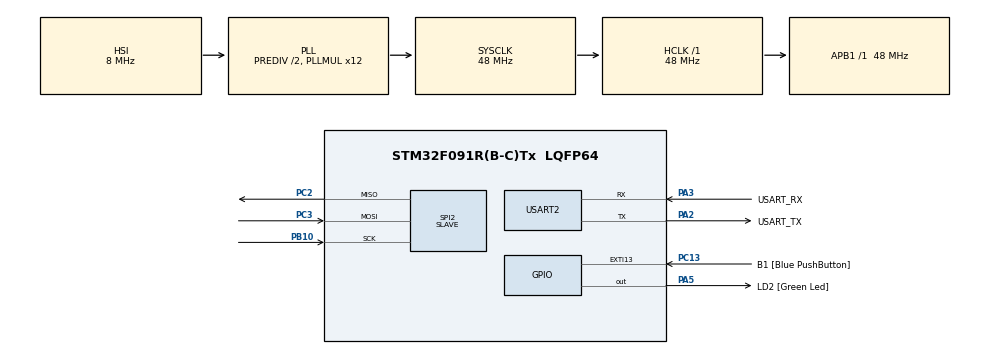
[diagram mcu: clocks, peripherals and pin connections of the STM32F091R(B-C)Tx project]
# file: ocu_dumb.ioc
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Dma.Request0=SPI2_RX
Dma.Request1=SPI2_TX
Dma.SPI2_RX.0.Direction=DMA_PERIPH_TO_MEMORY
Dma.SPI2_RX.0.Instance=DMA1_Channel4
Dma.SPI2_RX.0.MemDataAlignment=DMA_MDATAALIGN_BYTE
Dma.SPI2_RX.0.MemInc=DMA_MINC_ENABLE
Dma.SPI2_RX.0.Mode=DMA_NORMAL
Dma.SPI2_RX.0.PeriphDataAlignment=DMA_PDATAALIGN_BYTE
Dma.SPI2_RX.0.PeriphInc=DMA_PINC_DISABLE
Dma.SPI2_RX.0.Priority=DMA_PRIORITY_LOW
Dma.SPI2_TX.1.Direction=DMA_MEMORY_TO_PERIPH
Dma.SPI2_TX.1.Instance=DMA1_Channel5
Dma.SPI2_TX.1.MemDataAlignment=DMA_MDATAALIGN_BYTE
Dma.SPI2_TX.1.MemInc=DMA_MINC_ENABLE
Dma.SPI2_TX.1.Mode=DMA_NORMAL
Dma.SPI2_TX.1.PeriphDataAlignment=DMA_PDATAALIGN_BYTE
Dma.SPI2_TX.1.PeriphInc=DMA_PINC_DISABLE
Dma.SPI2_TX.1.Priority=DMA_PRIORITY_LOW
Mcu.Family=STM32F0
Mcu.Name=STM32F091R(B-C)Tx
Mcu.Package=LQFP64
NVIC.DMA1_Ch4_7_DMA2_Ch3_5_IRQn=true\:0\:0\:false\:false\:true\:false\:true
NVIC.SPI2_IRQn=true\:0\:0\:false\:false\:true\:true\:true
PA13.GPIO_Label=TMS
PA13.Mode=Serial_Wire
PA13.Signal=SYS_SWDIO
PA14.GPIO_Label=TCK
PA14.Mode=Serial_Wire
PA14.Signal=SYS_SWCLK
PA2.GPIO_Label=USART_TX
PA2.GPIO_Mode=GPIO_MODE_AF_PP
PA2.GPIO_PuPd=GPIO_NOPULL
PA2.GPIO_Speed=GPIO_SPEED_FREQ_LOW
PA2.Mode=Asynchronous
PA2.Signal=USART2_TX
PA3.GPIO_Label=USART_RX
PA3.GPIO_Mode=GPIO_MODE_AF_PP
PA3.GPIO_PuPd=GPIO_NOPULL
PA3.GPIO_Speed=GPIO_SPEED_FREQ_LOW
PA3.Mode=Asynchronous
PA3.Signal=USART2_RX
PA5.GPIO_Label=LD2 [Green Led]
PA5.GPIO_Mode=GPIO_MODE_OUTPUT_PP
PA5.GPIO_PuPd=GPIO_NOPULL
PA5.GPIO_Speed=GPIO_SPEED_FREQ_LOW
PA5.Signal=GPIO_Output
PB10.Mode=Full_Duplex_Slave
PB10.Signal=SPI2_SCK
PC13.GPIO_Label=B1 [Blue PushButton]
PC13.GPIO_ModeDefaultEXTI=GPIO_MODE_IT_FALLING
PC13.Signal=GPXTI13
PC14OSC32_IN.Mode=LSE-External-Oscillator
PC14OSC32_IN.Signal=RCC_OSC32_IN
PC15OSC32_OUT.Mode=LSE-External-Oscillator
PC15OSC32_OUT.Signal=RCC_OSC32_OUT
PC2.Mode=Full_Duplex_Slave
PC2.Signal=SPI2_MISO
PC3.Mode=Full_Duplex_Slave
PC3.Signal=SPI2_MOSI
PF0-OSC_IN.Mode=HSE-External-Clock-Source
PF0-OSC_IN.Signal=RCC_OSC_IN
PF1-OSC_OUT.Signal=RCC_OSC_OUT
ProjectManager.HeapSize=0x200
ProjectManager.StackSize=0x400
ProjectManager.TargetToolchain=STM32CubeIDE
RCC.AHBFreq_Value=48000000
RCC.APB1Freq_Value=48000000
RCC.APB1TimFreq_Value=48000000
RCC.FLatency-AdvancedSettings=FLASH_LATENCY_1
RCC.HCLKFreq_Value=48000000
RCC.PLLDivider=RCC_PREDIV_DIV2
RCC.PLLMUL=RCC_PLL_MUL12
RCC.PREFETCH_ENABLE-AdvancedSettings=1
RCC.SYSCLKFreq_VALUE=48000000
RCC.SYSCLKSource=RCC_SYSCLKSOURCE_PLLCLK
SPI2.Direction=SPI_DIRECTION_2LINES
SPI2.Mode=SPI_MODE_SLAVE
SPI2.VirtualType=VM_SLAVE
USART2.VirtualMode=VM_ASYNC
USART2.VirtualMode-Asynchronous=VM_ASYNC
board=NUCLEO-F091RC

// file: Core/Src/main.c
/* USER CODE BEGIN Header */
/**
  ******************************************************************************
  * @file           : main.c
  * @brief          : Main program body
  ******************************************************************************
  * @attention
  *
  * Copyright (c) 2022 STMicroelectronics.
  * All rights reserved.
  *
  * This software is licensed under terms that can be found in the LICENSE file
  * in the root directory of this software component.
  * If no LICENSE file comes with this software, it is provided AS-IS.
  *
  ******************************************************************************
  */
/* USER CODE END Header */
#include "main.h"

/* USER CODE BEGIN Includes */
#include "IntraSatComm.h"
/* USER CODE END Includes */

SPI_HandleTypeDef hspi2;
DMA_HandleTypeDef hdma_spi2_rx;
DMA_HandleTypeDef hdma_spi2_tx;

UART_HandleTypeDef huart2;

/* USER CODE BEGIN PV */
uint8_t receive_buffer[12];
uint8_t buffer_arg[12];
/* USER CODE END PV */

void SystemClock_Config(void);
static void MX_GPIO_Init(void);
static void MX_USART2_UART_Init(void);
static void MX_DMA_Init(void);
static void MX_SPI2_Init(void);

/* USER CODE BEGIN 0 */
void OBC_RX(){
	HAL_SPI_Receive(&hspi2, receive_buffer,sizeof(receive_buffer),HAL_MAX_DELAY);
	PacketDiassemble(&id,&len,&cmd,buffer_arg, receive_buffer, length);
}
/* USER CODE END 0 */

int main(void)
{

  /* MCU Configuration--------------------------------------------------------*/

  /* Reset of all peripherals, Initializes the Flash interface and the Systick. */
  HAL_Init();

  /* Configure the system clock */
  SystemClock_Config();

  /* Initialize all configured peripherals */
  MX_GPIO_Init();
  MX_USART2_UART_Init();
  MX_DMA_Init();
  MX_SPI2_Init();

  /* Infinite loop */
  while (1)
  {

  }
}

void SystemClock_Config(void)
{
  RCC_OscInitTypeDef RCC_OscInitStruct = {0};
  RCC_ClkInitTypeDef RCC_ClkInitStruct = {0};
  RCC_PeriphCLKInitTypeDef PeriphClkInit = {0};

  /** Initializes the RCC Oscillators according to the specified parameters
  * in the RCC_OscInitTypeDef structure.
  */
  RCC_OscInitStruct.OscillatorType = RCC_OSCILLATORTYPE_HSI;
  RCC_OscInitStruct.HSIState = RCC_HSI_ON;
  RCC_OscInitStruct.HSICalibrationValue = RCC_HSICALIBRATION_DEFAULT;
  RCC_OscInitStruct.PLL.PLLState = RCC_PLL_ON;
  RCC_OscInitStruct.PLL.PLLSource = RCC_PLLSOURCE_HSI;
  RCC_OscInitStruct.PLL.PLLMUL = RCC_PLL_MUL12;
  RCC_OscInitStruct.PLL.PREDIV = RCC_PREDIV_DIV2;
  if (HAL_RCC_OscConfig(&RCC_OscInitStruct) != HAL_OK)
  {
    Error_Handler();
  }
  /** Initializes the CPU, AHB and APB buses clocks
  */
  RCC_ClkInitStruct.ClockType = RCC_CLOCKTYPE_HCLK|RCC_CLOCKTYPE_SYSCLK
                              |RCC_CLOCKTYPE_PCLK1;
  RCC_ClkInitStruct.SYSCLKSource = RCC_SYSCLKSOURCE_PLLCLK;
  RCC_ClkInitStruct.AHBCLKDivider = RCC_SYSCLK_DIV1;
  RCC_ClkInitStruct.APB1CLKDivider = RCC_HCLK_DIV1;

  if (HAL_RCC_ClockConfig(&RCC_ClkInitStruct, FLASH_LATENCY_1) != HAL_OK)
  {
    Error_Handler();
  }
  PeriphClkInit.PeriphClockSelection = RCC_PERIPHCLK_USART2;
  PeriphClkInit.Usart2ClockSelection = RCC_USART2CLKSOURCE_PCLK1;
  if (HAL_RCCEx_PeriphCLKConfig(&PeriphClkInit) != HAL_OK)
  {
    Error_Handler();
  }
}

static void MX_SPI2_Init(void)
{

  /* SPI2 parameter configuration*/
  hspi2.Instance = SPI2;
  hspi2.Init.Mode = SPI_MODE_SLAVE;
  hspi2.Init.Direction = SPI_DIRECTION_2LINES;
  hspi2.Init.DataSize = SPI_DATASIZE_4BIT;
  hspi2.Init.CLKPolarity = SPI_POLARITY_LOW;
  hspi2.Init.CLKPhase = SPI_PHASE_1EDGE;
  hspi2.Init.NSS = SPI_NSS_SOFT;
  hspi2.Init.FirstBit = SPI_FIRSTBIT_MSB;
  hspi2.Init.TIMode = SPI_TIMODE_DISABLE;
  hspi2.Init.CRCCalculation = SPI_CRCCALCULATION_DISABLE;
  hspi2.Init.CRCPolynomial = 7;
  hspi2.Init.CRCLength = SPI_CRC_LENGTH_DATASIZE;
  hspi2.Init.NSSPMode = SPI_NSS_PULSE_DISABLE;
  if (HAL_SPI_Init(&hspi2) != HAL_OK)
  {
    Error_Handler();
  }

}

static void MX_USART2_UART_Init(void)
{

  huart2.Instance = USART2;
  huart2.Init.BaudRate = 115200;
  huart2.Init.WordLength = UART_WORDLENGTH_8B;
  huart2.Init.StopBits = UART_STOPBITS_1;
  huart2.Init.Parity = UART_PARITY_NONE;
  huart2.Init.Mode = UART_MODE_TX_RX;
  huart2.Init.HwFlowCtl = UART_HWCONTROL_NONE;
  huart2.Init.OverSampling = UART_OVERSAMPLING_16;
  huart2.Init.OneBitSampling = UART_ONE_BIT_SAMPLE_DISABLE;
  huart2.AdvancedInit.AdvFeatureInit = UART_ADVFEATURE_NO_INIT;
  if (HAL_UART_Init(&huart2) != HAL_OK)
  {
    Error_Handler();
  }

}

static void MX_DMA_Init(void)
{

  /* DMA controller clock enable */
  __HAL_RCC_DMA1_CLK_ENABLE();

  /* DMA interrupt init */
  /* DMA1_Ch4_7_DMA2_Ch3_5_IRQn interrupt configuration */
  HAL_NVIC_SetPriority(DMA1_Ch4_7_DMA2_Ch3_5_IRQn, 0, 0);
  HAL_NVIC_EnableIRQ(DMA1_Ch4_7_DMA2_Ch3_5_IRQn);

}

static void MX_GPIO_Init(void)
{
  GPIO_InitTypeDef GPIO_InitStruct = {0};

  /* GPIO Ports Clock Enable */
  __HAL_RCC_GPIOC_CLK_ENABLE();
  __HAL_RCC_GPIOF_CLK_ENABLE();
  __HAL_RCC_GPIOA_CLK_ENABLE();
  __HAL_RCC_GPIOB_CLK_ENABLE();

  /*Configure GPIO pin Output Level */
  HAL_GPIO_WritePin(GPIOA, GPIO_PIN_5, GPIO_PIN_RESET);

  /*Configure GPIO pin : PC13 */
  GPIO_InitStruct.Pin = GPIO_PIN_13;
  GPIO_InitStruct.Mode = GPIO_MODE_IT_FALLING;
  GPIO_InitStruct.Pull = GPIO_NOPULL;
  HAL_GPIO_Init(GPIOC, &GPIO_InitStruct);

  /*Configure GPIO pin : PA5 */
  GPIO_InitStruct.Pin = GPIO_PIN_5;
  GPIO_InitStruct.Mode = GPIO_MODE_OUTPUT_PP;
  GPIO_InitStruct.Pull = GPIO_NOPULL;
  GPIO_InitStruct.Speed = GPIO_SPEED_FREQ_LOW;
  HAL_GPIO_Init(GPIOA, &GPIO_InitStruct);

}

void Error_Handler(void)
{
  __disable_irq();
  while (1)
  {
  }
}
